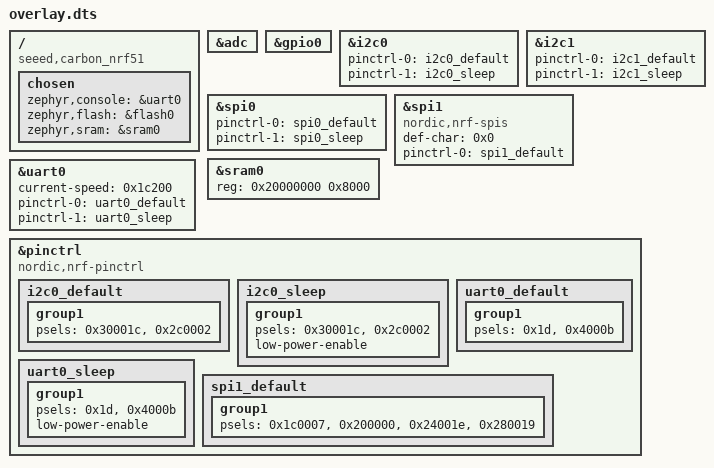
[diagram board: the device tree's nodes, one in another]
/ {
	compatible = "seeed,carbon_nrf51";
	chosen {
		zephyr,console = &uart0;
		zephyr,flash = &flash0;
		zephyr,sram = &sram0;
	};
};
&adc{
	status = "okay";
};
&gpio0{
	status = "okay";
};
&i2c0{
	status = "okay";
	pinctrl-0 = < &i2c0_default >;
	pinctrl-1 = < &i2c0_sleep >;
	pinctrl-names = "default", "sleep";
};
&i2c1{
	pinctrl-0 = < &i2c1_default >;
	pinctrl-1 = < &i2c1_sleep >;
	pinctrl-names = "default", "sleep";
};
&spi0{
	pinctrl-0 = < &spi0_default >;
	pinctrl-1 = < &spi0_sleep >;
	pinctrl-names = "default", "sleep";
};
&spi1{
	compatible = "nordic,nrf-spis";
	status = "okay";
	def-char = < 0x0 >;
	pinctrl-0 = < &spi1_default >;
	pinctrl-names = "default";
};
&sram0{
	reg = < 0x20000000 0x8000 >;
};
&uart0{
	status = "okay";
	current-speed = < 0x1c200 >;
	pinctrl-0 = < &uart0_default >;
	pinctrl-1 = < &uart0_sleep >;
	pinctrl-names = "default", "sleep";
};
&pinctrl{
	compatible = "nordic,nrf-pinctrl";
	i2c0_default: i2c0_default {
		group1 {
			psels = < 0x30001c >, < 0x2c0002 >;
		};
	};
	i2c0_sleep: i2c0_sleep {
		group1 {
			psels = < 0x30001c >, < 0x2c0002 >;
			low-power-enable;
		};
	};
	uart0_default: uart0_default {
		group1 {
			psels = < 0x1d >, < 0x4000b >;
		};
	};
	uart0_sleep: uart0_sleep {
		group1 {
			psels = < 0x1d >, < 0x4000b >;
			low-power-enable;
		};
	};
	spi1_default: spi1_default {
		group1 {
			psels = < 0x1c0007 >, < 0x200000 >, < 0x24001e >, < 0x280019 >;
		};
	};
};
